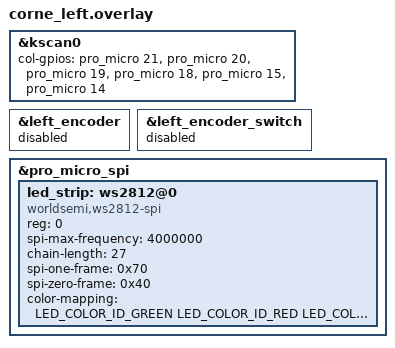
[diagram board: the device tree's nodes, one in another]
#include "corne.dtsi"

&kscan0 {
    col-gpios
        = <&pro_micro 21 GPIO_ACTIVE_HIGH>
        , <&pro_micro 20 GPIO_ACTIVE_HIGH>
        , <&pro_micro 19 GPIO_ACTIVE_HIGH>
        , <&pro_micro 18 GPIO_ACTIVE_HIGH>
        , <&pro_micro 15 GPIO_ACTIVE_HIGH>
        , <&pro_micro 14 GPIO_ACTIVE_HIGH>
        ;
};


&left_encoder {
	status = "disabled";
};

&left_encoder_switch {
    status = "disabled";
};

&pro_micro_spi {
    status = "okay";
    
    led_strip: ws2812@0 {
        compatible = "worldsemi,ws2812-spi";
        reg = <0>;
        spi-max-frequency = <4000000>;
        
        chain-length = <27>; // Move chain-length here
        spi-one-frame = <0x70>;
        spi-zero-frame = <0x40>;
        color-mapping = <LED_COLOR_ID_GREEN LED_COLOR_ID_RED LED_COLOR_ID_BLUE>;
    };
};

&led_strip {
    chain-length = <27>;
};
